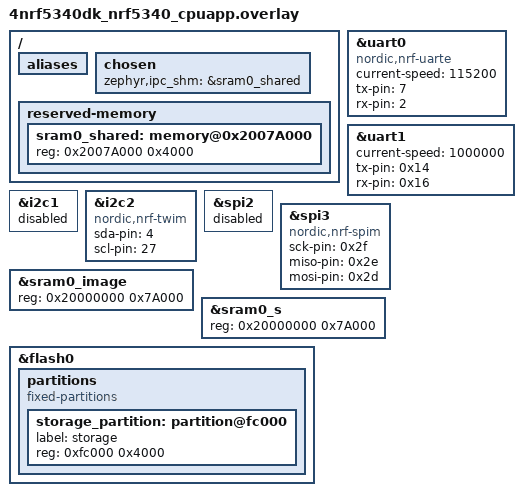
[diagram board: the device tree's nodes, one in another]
/* overlay file for app core */

&uart0 {
	compatible = "nordic,nrf-uarte";
	status = "okay";
	current-speed = < 115200 >;	
	tx-pin = < 7 >;
	rx-pin = < 2 >;
	/* delete rts-pin&cts-pin to release the related 2 pins for other uses */
	/delete-property/ rts-pin;
	/delete-property/ cts-pin;
};

&uart1 {
	status = "okay";
	current-speed = < 1000000 >;
	tx-pin = < 0x14 >;
	rx-pin = < 0x16 >;
};

&i2c1 {
	status = "disabled";
};

&i2c2 {
	status = "okay";
	compatible = "nordic,nrf-twim";
	sda-pin = <4>;
	scl-pin = <27>;
};

&spi2 {
	status = "disabled";
};

&spi3 {
	status = "okay"; 
	compatible = "nordic,nrf-spim";
	sck-pin = < 0x2f >;
	miso-pin = < 0x2e >;
	mosi-pin = < 0x2d >;
};

/* delete button3 to initialize the related pin for network core use */
/ {
 aliases {  
  /delete-property/ sw3;
 };
};

/delete-node/ &button3;

&sram0_image{
	reg = < 0x20000000 0x7A000 >;
};

&sram0_s{
	reg = < 0x20000000 0x7A000 >;
};

/delete-node/ &sram0_shared;

/ {
	chosen {
		/* shared memory reserved for the inter-processor communication */
		zephyr,ipc_shm = &sram0_shared;
	};

	reserved-memory {
		#address-cells = <1>;
		#size-cells = <1>;
		ranges;	
		sram0_shared: memory@0x2007A000 {
			/* SRAM allocated to shared memory */
			reg = <0x2007A000 0x4000>;
		};
	};
};

/delete-node/ &storage_partition;
&flash0{
		partitions {
			compatible = "fixed-partitions";
			#address-cells = < 0x1 >;
			#size-cells = < 0x1 >;

			storage_partition: partition@fc000 {
				label = "storage";
				reg = < 0xfc000 0x4000 >;
			};
		};
};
